// Generated with Intrepid LIN LDF Tool

LIN_description_file ;

LIN_protocol_version = "2.1";
LIN_language_version = "2.1";
LIN_speed = L19.2 kbps;
Channel_name = "ZGW_LIN_4  ";

Nodes {
  Master: ZGW, 10 ms, 5 ms;
  Slaves: HVDCDC;
}

Signals {
  HVDCDC_ResponseError: 1, 1, HVDCDC, ZGW;
  HVDCDC_LV_Voltage: 8, 0, HVDCDC, ZGW;
  HVDCDC_LV_Current: 8, 0, HVDCDC, ZGW;
  HVDCDC_HV_Voltage: 8, 0, HVDCDC, ZGW;
  HVDCDC_HV_Current: 8, 0, HVDCDC, ZGW;
  HVDCDC_ChargingActive: 1, 0, HVDCDC, ZGW;
  ZGW_Enable_HVDCDC: 1, 0, ZGW, HVDCDC;
  ZGW_TargetVoltage_HVDCDC: 8, 0, ZGW, HVDCDC;
  ZGW_SDAT_Minute: 6, 0, ZGW, HVDCDC;
  ZGW_SDAT_TimeSource: 2, 3, ZGW, HVDCDC;
  ZGW_SDAT_Second: 6, 0, ZGW, HVDCDC;
  ZGW_SDAT_UtcValid: 1, 0, ZGW, HVDCDC;
  ZGW_SDAT_DefaultTime: 1, 0, ZGW, HVDCDC;
  ZGW_SDAT_Year: 6, 0, ZGW, HVDCDC;
  ZGW_SDAT_NvmRestored: 1, 0, ZGW, HVDCDC;
  ZGW_SDAT_Day: 5, 0, ZGW, HVDCDC;
  ZGW_SDAT_Hour: 5, 0, ZGW, HVDCDC;
  ZGW_SDAT_Month: 4, 0, ZGW, HVDCDC;
  ZGW_SDAT_Millisecond: 8, 0, ZGW, HVDCDC;
}

Frames {
  HVDCDC_Status: 0x0B, HVDCDC, 5 {
    HVDCDC_ResponseError, 0;
    HVDCDC_LV_Voltage, 1;
    HVDCDC_LV_Current, 2;
    HVDCDC_HV_Voltage, 3;
    HVDCDC_HV_Current, 4;
  }
  ZGW_Request_HVDCDC: 0x03, ZGW, 2 {
    ZGW_Enable_HVDCDC, 0;
    ZGW_TargetVoltage_HVDCDC, 1;
  }
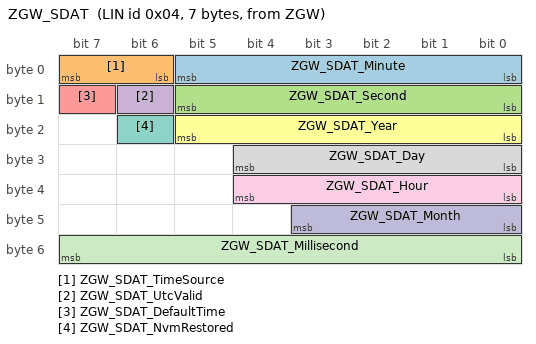
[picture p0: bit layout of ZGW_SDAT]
  ZGW_SDAT: 0x04, ZGW, 7 {
    ZGW_SDAT_Minute, 0;
    ZGW_SDAT_TimeSource, 6;
    ZGW_SDAT_Second, 8;
    ZGW_SDAT_UtcValid, 14;
    ZGW_SDAT_DefaultTime, 15;
    ZGW_SDAT_Year, 16;
    ZGW_SDAT_NvmRestored, 22;
    ZGW_SDAT_Day, 24;
    ZGW_SDAT_Hour, 32;
    ZGW_SDAT_Month, 40;
    ZGW_SDAT_Millisecond, 48;
  }
}

Diagnostic_frames {
     MasterReq: 60 {
  MasterReqB0:0;
  MasterReqB1:8;
  MasterReqB2:16;
  MasterReqB3:24;
  MasterReqB4:32;
  MasterReqB5:40;
  MasterReqB6:48;
  MasterReqB7:56;
     }
  SlaveResp: 61 {
  SlaveRespB0:0;
  SlaveRespB1:8;
  SlaveRespB2:16;
  SlaveRespB3:24;
  SlaveRespB4:32;
  SlaveRespB5:40;
  SlaveRespB6:48;
  SlaveRespB7:56;
     }
}

Node_attributes {
  HVDCDC {
    LIN_protocol = "2.1";
    configured_NAD = L4;
    product_id = L0x12346,3,3;
    response_error = LHVDCDC_ResponseError;
    fault_state_signals = LHVDCDC_ResponseError;
    P2_min = L50 ms;
    ST_min = L0 ms;
    configurable_frames {
      HVDCDC_Status;
      ZGW_Request_HVDCDC;
      ZGW_SDAT;
    }
  }
}

Schedule_tables {
  ZGW_LIN_4_Normal_Schedule_Table {
    ZGW_Request_HVDCDC delay 10 ms;
    HVDCDC_Status delay 10 ms;
    ZGW_SDAT delay 10 ms;
  }
  ZGW_LIN_4_Diagnostics_Schedule_Table {
    MasterReq delay 10 ms;
    SlaveResp delay 10 ms;
  }
}

Signal_encoding_types {
}

Signal_representation {
}
